VERSION ""

NS_ :

BS_:

BU_: EMS BMS DCDC BRM

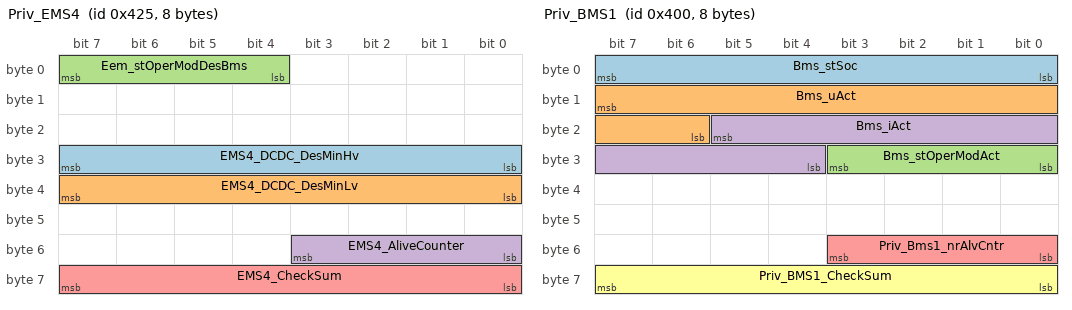
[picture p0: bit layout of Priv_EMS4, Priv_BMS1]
BO_ 1061 Priv_EMS4: 8 EMS
 SG_ EMS4_DCDC_DesMinHv : 31|8@0+ (0.25,0) [0|63.75] "V"  DCDC
 SG_ EMS4_DCDC_DesMinLv : 39|8@0+ (0.125,0) [0|31.875] "V"  DCDC
 SG_ Eem_stOperModDesBms : 7|4@0+ (1,0) [0|15] ""  BMS
 SG_ EMS4_AliveCounter : 51|4@0+ (1,0) [0|15] ""  BMS,DCDC
 SG_ EMS4_CheckSum : 63|8@0+ (1,0) [0|255] ""  BMS

BO_ 1024 Priv_BMS1: 8 BMS
 SG_ Bms_stSoc : 7|8@0+ (1,0) [0|100] "%"  EMS
 SG_ Bms_uAct : 15|10@0+ (0.1,0) [0|102.1] "V"  EMS
 SG_ Bms_stOperModAct : 27|4@0+ (1,0) [0|15] ""  EMS
 SG_ Bms_iAct : 21|10@0+ (1,-500) [-500|521] "A"  EMS
 SG_ Priv_Bms1_nrAlvCntr : 51|4@0+ (1,0) [0|15] ""  EMS
 SG_ Priv_BMS1_CheckSum : 63|8@0+ (1,0) [0|255] ""  EMS

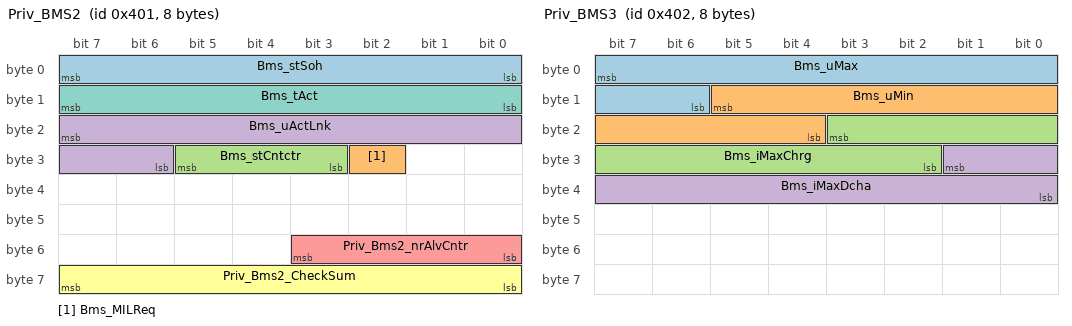
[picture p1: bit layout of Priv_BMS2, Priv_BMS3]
BO_ 1025 Priv_BMS2: 8 BMS
 SG_ Bms_stSoh : 7|8@0+ (1,0) [0|100] "%"  EMS
 SG_ Bms_MILReq : 26|1@0+ (1,0) [0|1] ""  EMS
 SG_ Bms_stCntctr : 29|3@0+ (1,0) [0|3] ""  EMS
 SG_ Bms_uActLnk : 23|10@0+ (0.1,0) [0|102.1] "V"  EMS
 SG_ Priv_Bms2_nrAlvCntr : 51|4@0+ (1,0) [0|15] ""  EMS
 SG_ Priv_Bms2_CheckSum : 63|8@0+ (1,0) [0|255] ""  EMS
 SG_ Bms_tAct : 15|8@0+ (1,-50) [-50|203] "°C"  EMS

BO_ 1026 Priv_BMS3: 8 BMS
 SG_ Bms_uMax : 7|10@0+ (0.1,0) [0|102.1] "V"  EMS
 SG_ Bms_uMin : 13|10@0+ (0.1,0) [0|102.1] "V"  EMS
 SG_ Bms_iMaxChrg : 19|10@0+ (1,-500) [-500|521] "A"  EMS
 SG_ Bms_iMaxDcha : 25|10@0+ (1,-500) [-500|521] "A"  EMS

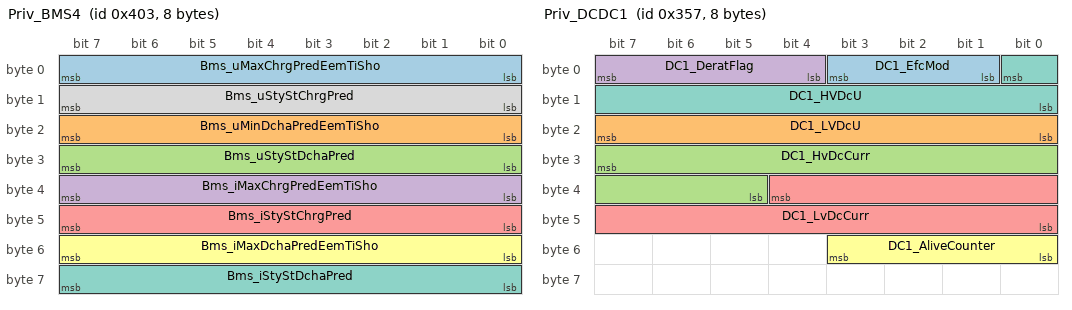
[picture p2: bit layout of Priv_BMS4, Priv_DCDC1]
BO_ 1027 Priv_BMS4: 8 BMS
 SG_ Bms_uMaxChrgPredEemTiSho : 7|8@0+ (0.25,10) [10|70] "V"  EMS
 SG_ Bms_uMinDchaPredEemTiSho : 23|8@0+ (0.25,0) [0|60] "V"  EMS
 SG_ Bms_uStyStDchaPred : 31|8@0+ (0.25,0) [0|60] "V"  EMS
 SG_ Bms_iMaxChrgPredEemTiSho : 39|8@0+ (2,0) [0|500] "A"  EMS
 SG_ Bms_iStyStChrgPred : 47|8@0+ (2,0) [0|500] "A"  EMS
 SG_ Bms_iMaxDchaPredEemTiSho : 55|8@0+ (2,-500) [-500|0] "A"  EMS
 SG_ Bms_iStyStDchaPred : 63|8@0+ (2,-500) [-500|0] "A"  EMS
 SG_ Bms_uStyStChrgPred : 15|8@0+ (0.25,10) [10|70] "V"  EMS

BO_ 855 Priv_DCDC1: 8 DCDC
 SG_ DC1_EfcMod : 3|3@0+ (1,0) [0|7] ""  EMS
 SG_ DC1_LVDcU : 23|8@0+ (0.125,0) [0|31.875] "V"  EMS
 SG_ DC1_HvDcCurr : 31|11@0+ (0.125,-128) [-128|127.875] "A"  EMS
 SG_ DC1_DeratFlag : 7|4@0+ (1,0) [0|12] ""  EMS
 SG_ DC1_LvDcCurr : 36|13@0+ (0.125,-512) [-512|511.875] "A"  EMS
 SG_ DC1_AliveCounter : 51|4@0+ (1,0) [0|15] ""  EMS
 SG_ DC1_HVDcU : 0|9@0+ (0.25,0) [0|127.75] "V"  EMS

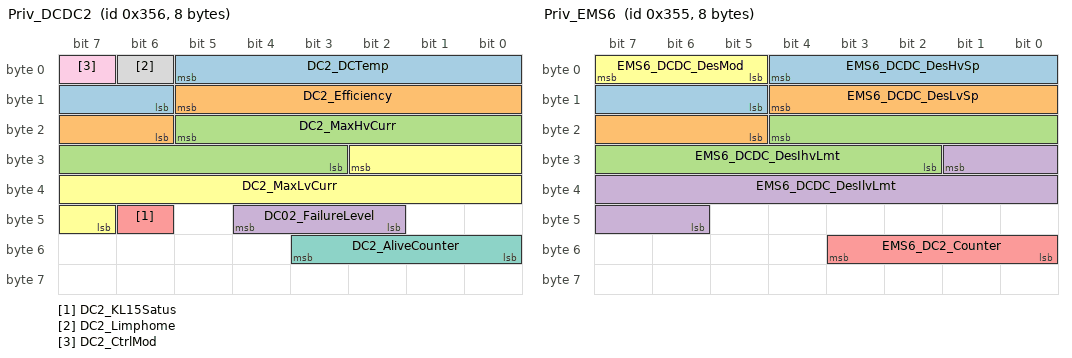
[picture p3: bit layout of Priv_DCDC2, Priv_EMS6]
BO_ 854 Priv_DCDC2: 8 DCDC
 SG_ DC2_DCTemp : 5|8@0+ (1,-40) [-40|215] "%"  EMS
 SG_ DC2_Efficiency : 13|8@0+ (0.00390625,0) [0|0.99609375] ""  EMS
 SG_ DC2_MaxHvCurr : 21|11@0+ (0.0625,-128) [-128|-0.0625] "A"  EMS
 SG_ DC02_FailureLevel : 44|3@0+ (1,0) [0|7] ""  EMS
 SG_ DC2_KL15Satus : 46|1@0+ (1,0) [0|1] ""  EMS
 SG_ DC2_MaxLvCurr : 26|12@0+ (0.125,0) [0|511.875] "A"  EMS
 SG_ DC2_AliveCounter : 51|4@0+ (1,0) [0|15] ""  EMS
 SG_ DC2_Limphome : 6|1@0+ (1,0) [0|1] ""  EMS
 SG_ DC2_CtrlMod : 7|1@0+ (1,0) [0|1] ""  EMS

BO_ 853 Priv_EMS6: 8 EMS
 SG_ EMS6_DCDC_DesHvSp : 4|8@0+ (0.25,0) [0|63.75] "V"  DCDC
 SG_ EMS6_DCDC_DesLvSp : 12|8@0+ (0.125,0) [0|31.875] "V"  DCDC
 SG_ EMS6_DCDC_DesIhvLmt : 20|11@0+ (0.0625,0) [0|127.9375] "A"  DCDC
 SG_ EMS6_DCDC_DesIlvLmt : 25|12@0+ (0.125,0) [0|511.875] "A"  DCDC
 SG_ EMS6_DC2_Counter : 51|4@0+ (1,0) [0|15] ""  DCDC
 SG_ EMS6_DCDC_DesMod : 7|3@0+ (1,0) [0|4] ""  DCDC

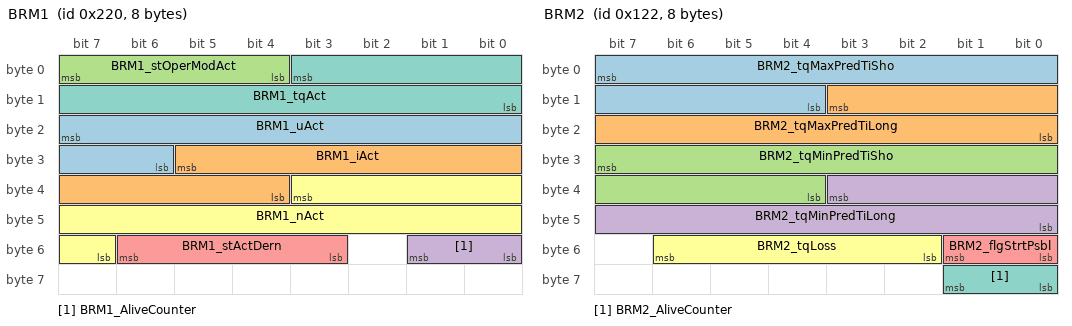
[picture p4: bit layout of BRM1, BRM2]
BO_ 544 BRM1: 8 BRM
 SG_ BRM1_uAct : 23|10@0+ (0.0625,0) [0|63.875] "V"  EMS
 SG_ BRM1_iAct : 29|10@0+ (1,-500) [-500|500] "A"  EMS
 SG_ BRM1_stOperModAct : 7|4@0+ (1,0) [0|15] ""  EMS
 SG_ BRM1_AliveCounter : 49|2@0+ (1,0) [0|3] ""  EMS
 SG_ BRM1_stActDern : 54|4@0+ (1,0) [0|15] ""  EMS
 SG_ BRM1_nAct : 35|13@0+ (6,-24000) [-24000|24000] "rpm"  EMS
 SG_ BRM1_tqAct : 3|12@0+ (0.125,-150) [-150|150] "Nm"  EMS

BO_ 290 BRM2: 8 BRM
 SG_ BRM2_tqMaxPredTiSho : 7|12@0+ (0.125,-150) [-150|150] "Nm"  EMS
 SG_ BRM2_tqMaxPredTiLong : 11|12@0+ (0.125,-150) [-150|150] "Nm"  EMS
 SG_ BRM2_tqMinPredTiSho : 31|12@0+ (0.125,-150) [-150|150] "Nm"  EMS
 SG_ BRM2_tqMinPredTiLong : 35|12@0+ (0.125,-150) [-150|150] "Nm"  EMS
 SG_ BRM2_flgStrtPsbl : 49|2@0+ (1,0) [0|3] ""  EMS
 SG_ BRM2_tqLoss : 54|5@0+ (0.125,-1.5) [-1.5|1.5] "Nm"  EMS
 SG_ BRM2_AliveCounter : 57|2@0+ (1,0) [0|3] ""  EMS

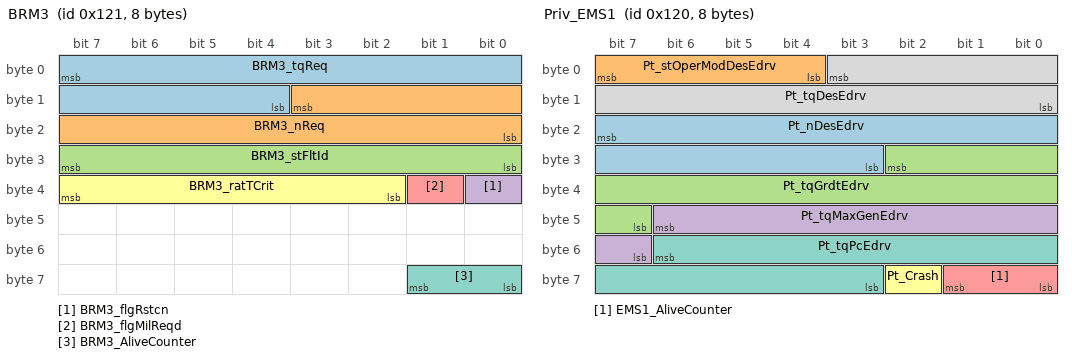
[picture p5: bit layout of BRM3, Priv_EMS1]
BO_ 289 BRM3: 8 BRM
 SG_ BRM3_tqReq : 7|12@0+ (0.125,-150) [-150|150] "Nm"  EMS
 SG_ BRM3_nReq : 11|12@0+ (6,0) [0|24000] "rpm"  EMS
 SG_ BRM3_stFltId : 31|8@0+ (1,0) [0|254] ""  EMS
 SG_ BRM3_flgRstcn : 32|1@0+ (1,0) [0|1] ""  EMS
 SG_ BRM3_flgMilReqd : 33|1@0+ (1,0) [0|1] ""  EMS
 SG_ BRM3_ratTCrit : 39|6@0+ (2,0) [0|100] "%"  EMS
 SG_ BRM3_AliveCounter : 57|2@0+ (1,0) [0|3] ""  EMS

BO_ 288 Priv_EMS1: 8 EMS
 SG_ Pt_nDesEdrv : 23|13@0+ (6,-24000) [-24000|24000] "rpm"  BRM
 SG_ Pt_stOperModDesEdrv : 7|4@0+ (1,0) [0|15] ""  BRM
 SG_ Pt_tqGrdtEdrv : 26|12@0+ (1,0) [0|4000] "Nm/Sec"  BRM
 SG_ Pt_tqMaxGenEdrv : 46|8@0+ (1,-150) [-150|0] "Nm"  BRM
 SG_ EMS1_AliveCounter : 57|2@0+ (1,0) [0|3] ""  BRM
 SG_ Pt_Crash : 58|1@0+ (1,0) [0|1] ""  BRM
 SG_ Pt_tqPcEdrv : 54|12@0+ (0.125,-150) [-150|150] "Nm"  BRM
 SG_ Pt_tqDesEdrv : 3|12@0+ (0.125,-150) [-150|150] "Nm"  BRM

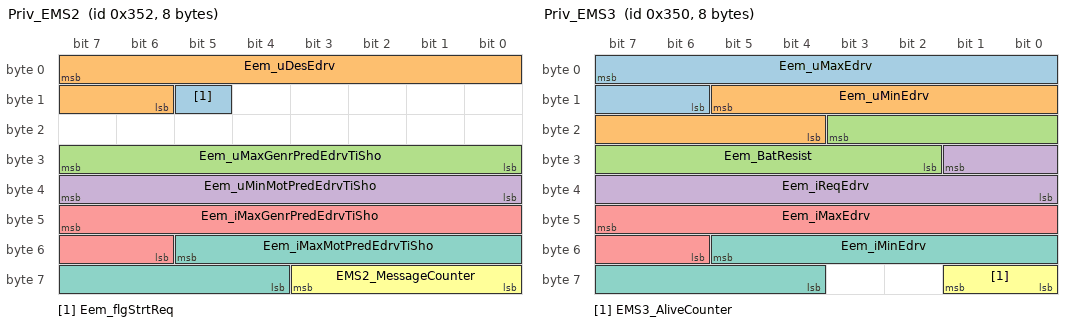
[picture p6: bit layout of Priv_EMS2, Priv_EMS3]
BO_ 850 Priv_EMS2: 8 EMS
 SG_ Eem_flgStrtReq : 13|1@0+ (1,0) [0|1] ""  BRM
 SG_ Eem_uDesEdrv : 7|10@0+ (0.0625,0) [0|63.9375] "V"  BRM
 SG_ Eem_uMaxGenrPredEdrvTiSho : 31|8@0+ (0.25,10) [10|70] "V"  BRM
 SG_ Eem_uMinMotPredEdrvTiSho : 39|8@0+ (0.25,0) [0|60] "V"  BRM
 SG_ Eem_iMaxGenrPredEdrvTiSho : 47|10@0+ (1,-800) [-800|200] "A"  BRM
 SG_ EMS2_MessageCounter : 59|4@0+ (1,0) [0|15] ""  BRM
 SG_ Eem_iMaxMotPredEdrvTiSho : 53|10@0+ (1,-200) [-200|800] "A"  BRM

BO_ 848 Priv_EMS3: 8 EMS
 SG_ Eem_uMaxEdrv : 7|10@0+ (0.0625,0) [0|63.9375] "V"  BRM
 SG_ Eem_uMinEdrv : 13|10@0+ (0.0625,0) [0|63.9375] "V"  BRM
 SG_ Eem_BatResist : 19|10@0+ (0.001,0) [0|1.022] "Ohm"  BRM
 SG_ Eem_iReqEdrv : 25|10@0+ (1,-500) [-500|500] "A"  BRM
 SG_ Eem_iMaxEdrv : 47|10@0+ (1,0) [0|1000] "A"  BRM
 SG_ EMS3_AliveCounter : 57|2@0+ (1,0) [0|3] ""  BRM
 SG_ Eem_iMinEdrv : 53|10@0+ (1,-1000) [-1000|0] "A"  BRM

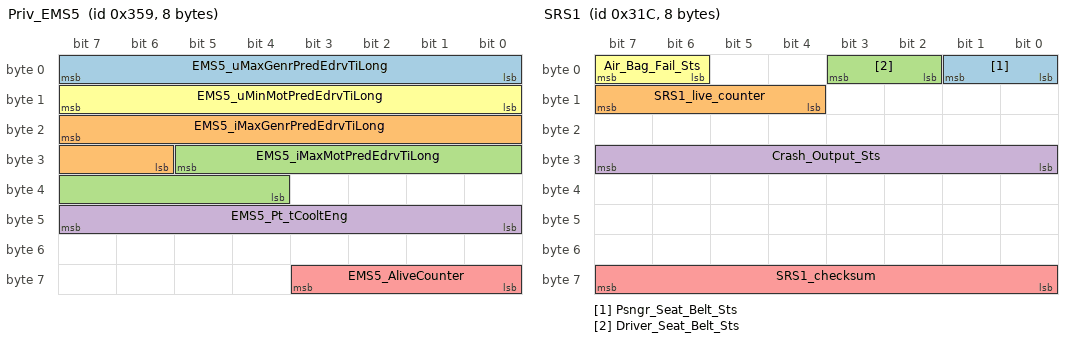
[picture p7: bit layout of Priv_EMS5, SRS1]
BO_ 857 Priv_EMS5: 8 EMS
 SG_ EMS5_uMaxGenrPredEdrvTiLong : 7|8@0+ (0.25,10) [10|70] "V"  BRM
 SG_ EMS5_iMaxGenrPredEdrvTiLong : 23|10@0+ (1,-800) [-800|200] "A"  BRM
 SG_ EMS5_iMaxMotPredEdrvTiLong : 29|10@0+ (1,-200) [-200|800] "A"  BRM
 SG_ EMS5_Pt_tCooltEng : 47|8@0+ (1,-40) [-40|215] "℃"  BRM
 SG_ EMS5_AliveCounter : 59|4@0+ (1,0) [0|15] ""  BRM
 SG_ EMS5_uMinMotPredEdrvTiLong : 15|8@0+ (0.25,0) [0|60] "V"  BRM

BO_ 796 SRS1: 8 EMS
 SG_ Psngr_Seat_Belt_Sts : 1|2@0+ (1,0) [0|3] "" Vector__XXX
 SG_ SRS1_live_counter : 15|4@0+ (1,0) [0|15] ""  BMS
 SG_ Driver_Seat_Belt_Sts : 3|2@0+ (1,0) [0|3] "" Vector__XXX
 SG_ Crash_Output_Sts : 31|8@0+ (1,0) [0|16] ""  BMS
 SG_ SRS1_checksum : 63|8@0+ (1,0) [0|255] ""  BMS
 SG_ Air_Bag_Fail_Sts : 7|2@0+ (1,0) [0|3] "" Vector__XXX
